# R7FA6T2BD register map
Vendor: Renesas Electronics Corporation; Series: RA6; File version: 1.40.00
CPU: CM33 r0p4, little endian, MPU, FPU, VTOR, 4 interrupt priority bits, 96 interrupts
Registers are 32-bit, read-write, reset 0x0 unless marked. A register's access mark holds for its fields unless they carry their own. Offsets are from the block's base; [hi:lo] are bit positions; {n}, {i} and the like mark numbered series.

## IIC0WU_B — Inter,Integrated Circuit 0 Wake,up Unit
Base 0x4011F098
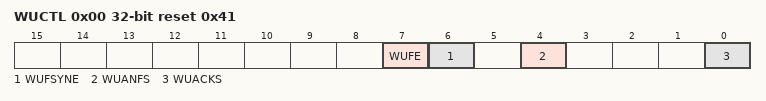
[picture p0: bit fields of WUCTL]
0x00 WUCTL reset 0x41 — Wake Up Unit Control Register
  [7] WUFE — Wake,Up function Enable
  [6] WUFSYNE — Wake,Up function PCLKA Synchronous Enable
  [4] WUANFS — Wake,Up Analog Noise Filter Selection
  [0] WUACKS — Wake,Up Acknowledge Selection
0x180 WUST ro — Wake Up Unit Operating Status Register
  [0] WUASYNF — Wake,up function asynchronous operation status flag

## ECCMB — CANFD ECC Module
Base 0x4012F200
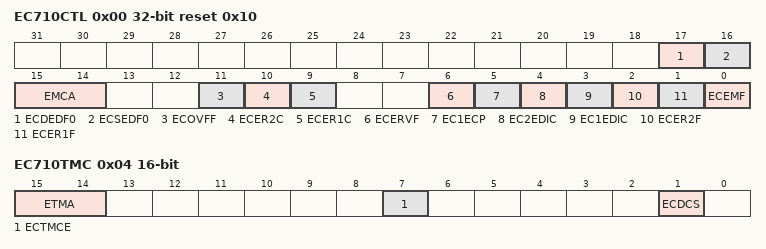
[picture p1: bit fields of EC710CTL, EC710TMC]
0x00 EC710CTL reset 0x10 — ECC Control Register
  [17] ECDEDF0 ro — ECC Dual Bit Error Address Detection Flag
  [16] ECSEDF0 ro — ECC Single bit Error Address Detection Flag
  [15:14] EMCA — Access Control to ECC Mode Select bit
  [11] ECOVFF ro — ECC Overflow Detection Flag
  [10] ECER2C — 2-bit ECC Error Detection Flag Clear
  [9] ECER1C — Accumulating ECC Error Detection and Correction Flag Clear
  [6] ECERVF — ECC Error Judgment Enable Flag
  [5] EC1ECP — ECC 1-bit Error Correction Permission
  [4] EC2EDIC — ECC 2-bit Error Detection Interrupt Control
  [3] EC1EDIC — ECC 1-bit Error Detection Interrupt Control
  [2] ECER2F ro — 2-bit ECC Error Detection Flag
  [1] ECER1F ro — ECC Error Detection and Correction Flag
  [0] ECEMF ro — ECC Error Message Flag
0x04 EC710TMC 16-bit — ECC Test Mode Control Register
  [15:14] ETMA — ECC Test Mode Bit Access Control
  [7] ECTMCE — ECC Test Mode Control Enable
  [1] ECDCS — ECC Decode Input Select
0x0C EC710TED — ECC Test Substitute Data Register
  [31:0] ECEDB — ECC Test Substitute Data
0x10 EC710EAD0 ro — ECC Error Address Register
  [10:0] ECEAD — ECC Error Address

## GPT_OPS — Output Phase Switching Controller
Base 0x40169A00
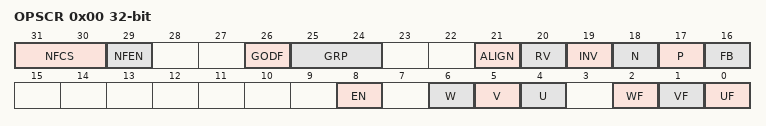
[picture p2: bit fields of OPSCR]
0x00 OPSCR — Output Phase Switching Control Register
  [31:30] NFCS — External Input Noise Filter Clock Selection
  [29] NFEN — External Input Noise Filter Enable
  [26] GODF — Group Output Disable Function
  [25:24] GRP — Output Disabled Source Selection
  [21] ALIGN — Input Phase Alignment
  [20] RV — Output Phase Rotation Direction Reversal Control
  [19] INV — Output Phase Invert Control
  [18] N — Negative,Phase Output (N) Control
  [17] P — Positive,Phase Output (P) Control
  [16] FB — External Feedback Signal Enable
  [8] EN — Output Phase Enable
  [6] W ro — Input W,Phase Monitor
  [5] V ro — Input V,Phase Monitor
  [4] U ro — Input U,Phase Monitor
  [2] WF
  [1] VF
  [0] UF

## GPT_GTCLK — GTCLK
Base 0x40169B00
0x00 GTCLKCR — General PWM Timer Clock Control Register
  [0] BPEN — Synchronization Circuit Bypass Enable

## PDG — PWM Delay Generation Circuit
Base 0x4016A000
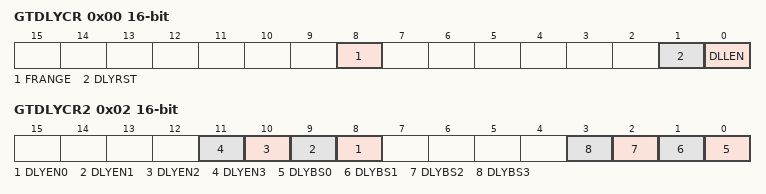
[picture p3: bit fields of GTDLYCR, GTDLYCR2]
0x00 GTDLYCR 16-bit — PWM Output Delay Control Register
  [8] FRANGE — GPT core clock Frequency Range
  [1] DLYRST — PWM Delay Generation Circuit Reset
  [0] DLLEN — DLL Operation Enable
0x02 GTDLYCR2 16-bit — PWM Output Delay Control Register 2
  [n+8] DLYEN{n} (n=0..3) — PWM Delay Generation Circuit enable for channel {n}
  [n] DLYBS{n} (n=0..3) — PWM Delay Generation Circuit bypass for channel {n}
{0x18+4i} GTDLYR{i}A (i=0..3) 16-bit — GTIOCnA Rising Output Delay Register
  [4:0] DLY — GTIOCnA Output Rising Edge Delay Setting
{0x1A+4i} GTDLYR{i}B (i=0..3) 16-bit — GTIOCnB Rising Output Delay Register
  [4:0] DLY — GTIOCnB Output Rising Edge Delay Setting
{0x28+4i} GTDLYF{i}A (i=0..3) 16-bit — GTIOCnA Falling Output Delay Register
  [4:0] DLY — GTIOCnA Output Falling Edge Delay Setting
{0x2A+4i} GTDLYF{i}B (i=0..3) 16-bit — GTIOCnB Falling Output Delay Register
  [4:0] DLY — GTIOCnB Output Falling Edge Delay Setting
